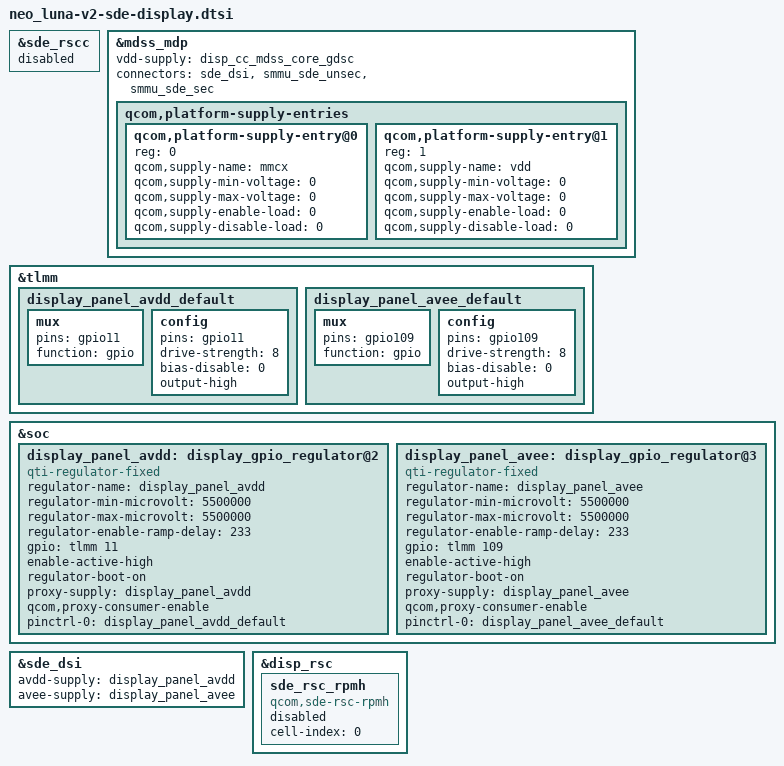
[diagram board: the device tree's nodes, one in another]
#include "neo-sde-display.dtsi"

&sde_rscc {
        status = "disabled";
};

&mdss_mdp {
	vdd-supply = <&disp_cc_mdss_core_gdsc>;

	qcom,platform-supply-entries {
		#address-cells = <1>;
		#size-cells = <0>;

		qcom,platform-supply-entry@0 {
			reg = <0>;
			qcom,supply-name = "mmcx";
			qcom,supply-min-voltage = <0>;
				qcom,supply-max-voltage = <0>;
				qcom,supply-enable-load = <0>;
				qcom,supply-disable-load = <0>;
		};

		qcom,platform-supply-entry@1 {
			reg = <1>;
			qcom,supply-name = "vdd";
			qcom,supply-min-voltage = <0>;
				qcom,supply-max-voltage = <0>;
				qcom,supply-enable-load = <0>;
				qcom,supply-disable-load = <0>;
		};
	};
};

&tlmm {
	display_panel_avdd_default: display_panel_avdd_default {
		mux {
			pins = "gpio11";
			function = "gpio";
		};

		config {
			pins = "gpio11";
			drive-strength = <8>;
			bias-disable = <0>;
			output-high;
		};
	};

	display_panel_avee_default: display_panel_avee_default {
		mux {
			pins = "gpio109";
			function = "gpio";
		};

		config {
			pins = "gpio109";
			drive-strength = <8>;
			bias-disable = <0>;
			output-high;
		};
	};
};

&soc {
	display_panel_avdd: display_gpio_regulator@2 {
		compatible = "qti-regulator-fixed";
		regulator-name = "display_panel_avdd";
		regulator-min-microvolt = <5500000>;
		regulator-max-microvolt = <5500000>;
		regulator-enable-ramp-delay = <233>;
		gpio = <&tlmm 11 0>;
		enable-active-high;
		regulator-boot-on;
		proxy-supply = <&display_panel_avdd>;
		qcom,proxy-consumer-enable;
		pinctrl-names = "default";
		pinctrl-0 = <&display_panel_avdd_default>;
	};

	display_panel_avee: display_gpio_regulator@3 {
		compatible = "qti-regulator-fixed";
		regulator-name = "display_panel_avee";
		regulator-min-microvolt = <5500000>;
		regulator-max-microvolt = <5500000>;
		regulator-enable-ramp-delay = <233>;
		gpio = <&tlmm 109 0>;
		enable-active-high;
		regulator-boot-on;
		proxy-supply = <&display_panel_avee>;
		qcom,proxy-consumer-enable;
		pinctrl-names = "default";
		pinctrl-0 = <&display_panel_avee_default>;
	};
};

&sde_dsi {
	avdd-supply = <&display_panel_avdd>;
	avee-supply = <&display_panel_avee>;
};

&disp_rsc {
	sde_rsc_rpmh {
	        status = "disabled";
		compatible = "qcom,sde-rsc-rpmh";
		cell-index = <0>;
	};
};

&mdss_mdp {
	connectors = <&sde_dsi &smmu_sde_unsec &smmu_sde_sec>;
};
